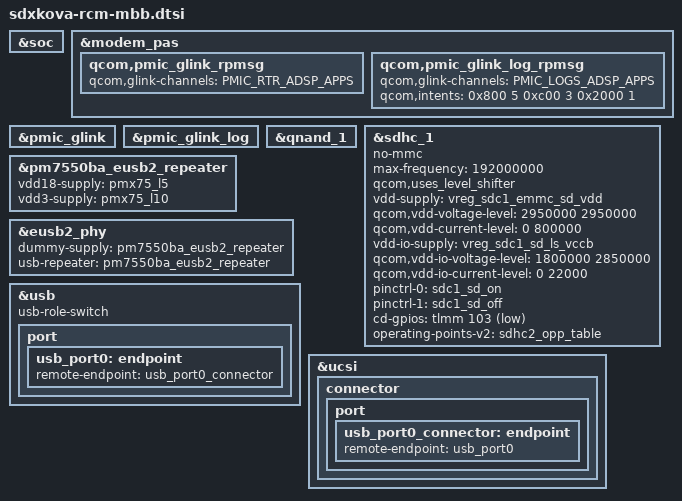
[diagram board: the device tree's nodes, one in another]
// SPDX-License-Identifier: BSD-3-Clause
/*
 * Copyright (c) 2024-2025 Qualcomm Innovation Center, Inc. All rights reserved.
 */

#include "sdxkova-pmic-overlay.dtsi"
#include "pm7550ba.dtsi"
#include <dt-bindings/gpio/gpio.h>

&soc {
};

&modem_pas {
	qcom,pmic_glink_rpmsg {
		qcom,glink-channels = "PMIC_RTR_ADSP_APPS";
	};

	qcom,pmic_glink_log_rpmsg {
		qcom,glink-channels = "PMIC_LOGS_ADSP_APPS";
		qcom,intents = <0x800 5
				0xc00 3
				0x2000 1>;
	};
};

&pmic_glink {
	status = "ok";
};

&pmic_glink_log {
	status = "ok";
};

&qnand_1 {
	status = "ok";
};

&sdhc_1 {
	status = "ok";

	no-mmc;
	max-frequency = <192000000>;

	qcom,uses_level_shifter;

	vdd-supply = <&vreg_sdc1_emmc_sd_vdd>;
	qcom,vdd-voltage-level = <2950000 2950000>;
	qcom,vdd-current-level = <0 800000>;

	vdd-io-supply = <&vreg_sdc1_sd_ls_vccb>;
	qcom,vdd-io-voltage-level = <1800000 2850000>;
	qcom,vdd-io-current-level = <0 22000>;

	pinctrl-names = "default", "sleep";
	pinctrl-0 = <&sdc1_sd_on>;
	pinctrl-1 = <&sdc1_sd_off>;

	cd-gpios = <&tlmm 103 GPIO_ACTIVE_LOW>;

	operating-points-v2 = <&sdhc2_opp_table>;
};

&pm7550ba_eusb2_repeater {
	vdd18-supply = <&pmx75_l5>;
	vdd3-supply = <&pmx75_l10>;
	status = "ok";
};

&eusb2_phy {
	dummy-supply = <&pm7550ba_eusb2_repeater>;
	usb-repeater = <&pm7550ba_eusb2_repeater>;
};

&usb {
	usb-role-switch;
	port {
		usb_port0: endpoint {
			remote-endpoint = <&usb_port0_connector>;
		};
	};
};

&ucsi {
	connector {
		port {
			usb_port0_connector: endpoint {
				remote-endpoint = <&usb_port0>;
			};
		};
	};
};
